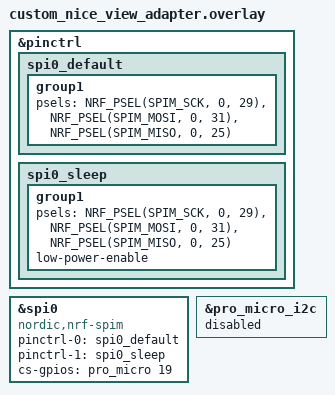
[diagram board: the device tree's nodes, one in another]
&pinctrl {   
    spi0_default: spi0_default {
        group1 {
            psels = <NRF_PSEL(SPIM_SCK, 0, 29)>, // SCL (P0.29/D20)
                <NRF_PSEL(SPIM_MOSI, 0, 31)>, // SDA (P0.31/D21)
                <NRF_PSEL(SPIM_MISO, 0, 25)>; // Not used but required
        };
    };
    spi0_sleep: spi0_sleep {
        group1 {
            psels = <NRF_PSEL(SPIM_SCK, 0, 29)>, // SCL (P0.29/D20)
                    <NRF_PSEL(SPIM_MOSI, 0, 31)>, // SDA (P0.31/D21)
                    <NRF_PSEL(SPIM_MISO, 0, 25)>; // Not used but required
            low-power-enable;
        };
    };         
};

nice_view_spi: &spi0 {
    compatible = "nordic,nrf-spim";
    pinctrl-0 = <&spi0_default>;
    pinctrl-1 = <&spi0_sleep>;
    pinctrl-names = "default", "sleep";
    cs-gpios = <&pro_micro 19 GPIO_ACTIVE_HIGH>; // CS (P0.02/D19)
};

&pro_micro_i2c {
    status = "disabled";
};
